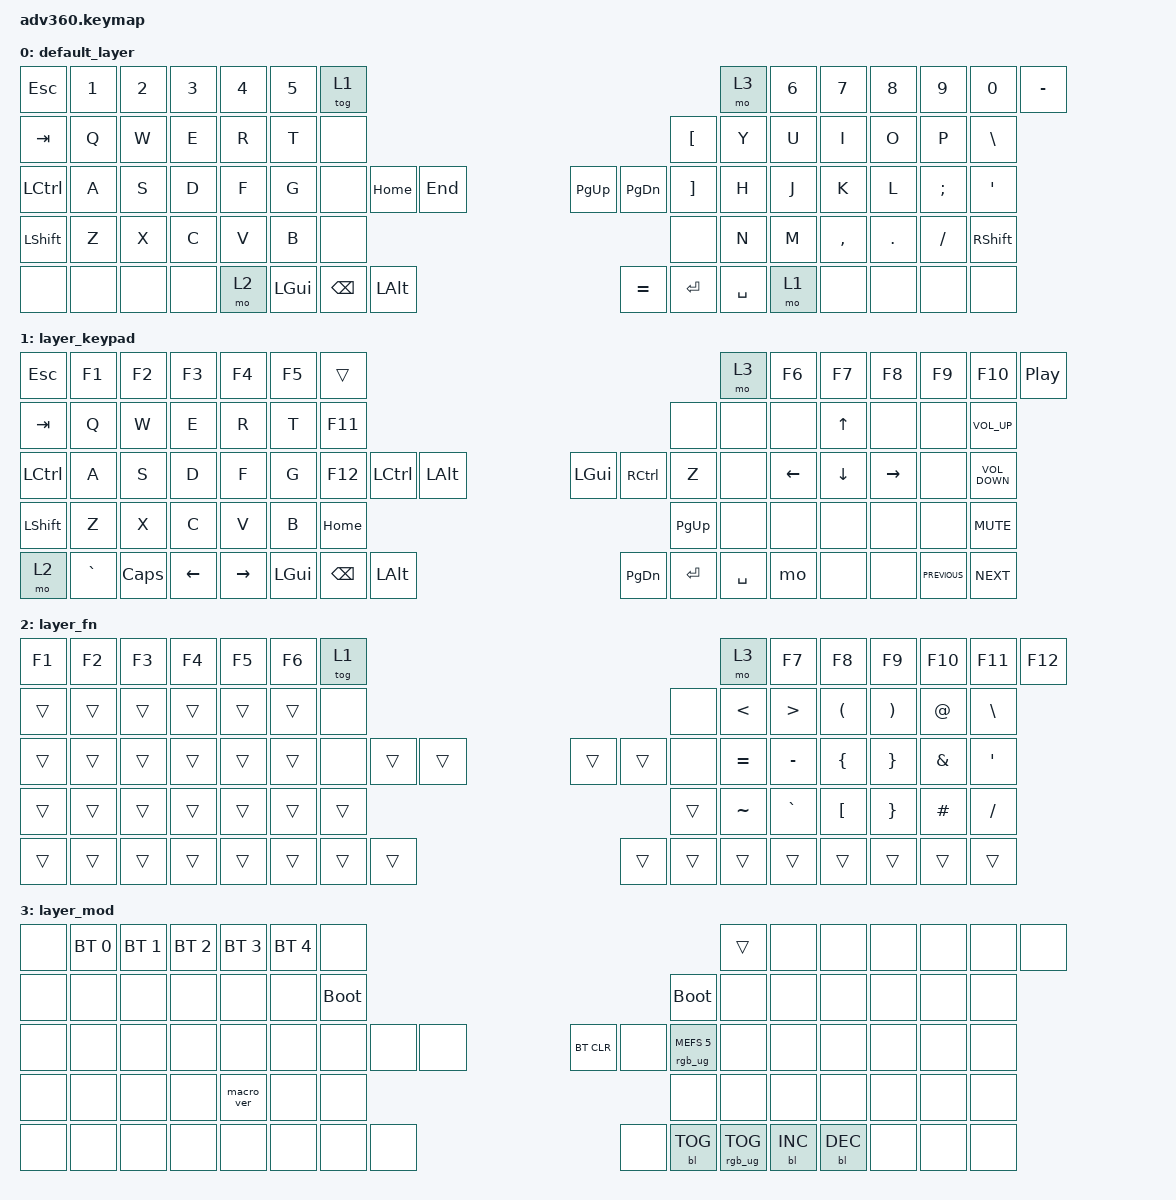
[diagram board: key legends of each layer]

/*
 * Copyright (c) 2020 The ZMK Contributors
 *
 * SPDX-License-Identifier: MIT
 */


/* THIS FILE WAS GENERATED!
 *
 * This file was generated automatically. You may or may not want to
 * edit it directly.
 */

#include <behaviors.dtsi>
#include <dt-bindings/zmk/keys.h>
#include <dt-bindings/zmk/bt.h>
#include <dt-bindings/zmk/rgb.h>
#include <dt-bindings/zmk/backlight.h>

/ {
  behaviors {
    #include "macros.dtsi"
    #include "version.dtsi"

    hm: homerow_mods {
        compatible = "zmk,behavior-hold-tap";
        label = "HOMEROW_MODS";
        #binding-cells = <2>;
        tapping-term-ms = <200>;
        quick_tap_ms = <175>;
        flavor = "tap-preferred";
        bindings = <&kp>, <&kp>;
    };
  };

    keymap {
        compatible = "zmk,keymap";


        default_layer {
            bindings = <
   &kp ESC  &kp N1  &kp N2  &kp N3  &kp N4  &kp N5                  &tog 1                                                                            &mo 3  &kp N6  &kp N7     &kp N8   &kp N9    &kp N0  &kp MINUS
   &kp TAB   &kp Q   &kp W   &kp E   &kp R   &kp T                   &none                                                                 &kp LEFT_BRACKET   &kp Y   &kp U      &kp I    &kp O     &kp P   &kp BSLH
 &kp LCTRL   &kp A   &kp S   &kp D   &kp F   &kp G                   &none  &kp HOME       &kp END                  &kp PG_UP  &kp PG_DN  &kp RIGHT_BRACKET   &kp H   &kp J      &kp K    &kp L  &kp SEMI    &kp SQT
 &kp LSHFT   &kp Z   &kp X   &kp C   &kp V   &kp B                                           &none                      &none                                 &kp N   &kp M  &kp COMMA  &kp DOT  &kp FSLH  &kp RSHFT
     &none   &none   &none   &none   &mo 2                    &kp LEFT_GUI  &kp BSPC  &kp LEFT_ALT                  &kp EQUAL  &kp ENTER          &kp SPACE           &mo 1      &none    &none     &none      &none
            >;
        };

        layer_keypad {
            bindings = <
   &kp ESC     &kp F1    &kp F2    &kp F3     &kp F4  &kp F5                  &trans                                                                         &mo 3  &kp F6    &kp F7        &kp F8     &kp F9         &kp F10   &kp C_PLAY_PAUSE
   &kp TAB      &kp Q     &kp W     &kp E      &kp R   &kp T                 &kp F11                                                                         &none   &none     &none  &kp UP_ARROW      &none           &none    &kp C_VOLUME_UP
 &kp LCTRL      &kp A     &kp S     &kp D      &kp F   &kp G                 &kp F12      &kp LCTRL      &kp LALT                   &kp LGUI  &kp RCTRL      &kp Z   &none  &kp LEFT      &kp DOWN  &kp RIGHT           &none  &kp C_VOLUME_DOWN
 &kp LSHFT      &kp Z     &kp X     &kp C      &kp V   &kp B                                             &kp HOME                  &kp PG_UP                         &none     &none         &none      &none           &none         &kp C_MUTE
     &mo 2  &kp GRAVE  &kp CAPS  &kp LEFT  &kp RIGHT                    &kp LEFT_GUI  &kp BACKSPACE  &kp LEFT_ALT                  &kp PG_DN  &kp ENTER  &kp SPACE               &mo         &none      &none  &kp C_PREVIOUS         &kp C_NEXT
            >;
        };

        layer_fn {
            bindings = <
 &kp F1  &kp F2  &kp F3  &kp F4  &kp F5  &kp F6            &tog 1                                                   &mo 3     &kp F7     &kp F8                &kp F9                &kp F10        &kp F11           &kp F12
 &trans  &trans  &trans  &trans  &trans  &trans             &none                                                   &none     &kp LT     &kp GT  &kp LEFT_PARENTHESIS  &kp RIGHT_PARENTHESIS    &kp AT_SIGN     &kp BACKSLASH
 &trans  &trans  &trans  &trans  &trans  &trans             &none  &trans  &trans                  &trans  &trans   &none  &kp EQUAL  &kp MINUS        &kp LEFT_BRACE        &kp RIGHT_BRACE  &kp AMPERSAND  &kp SINGLE_QUOTE
 &trans  &trans  &trans  &trans  &trans  &trans                            &trans                  &trans                  &kp TILDE  &kp GRAVE      &kp LEFT_BRACKET        &kp RIGHT_BRACE       &kp HASH         &kp SLASH
 &trans  &trans  &trans  &trans  &trans                    &trans  &trans  &trans                  &trans  &trans  &trans                &trans                &trans                 &trans         &trans            &trans
            >;
        };

        layer_mod {
            bindings = <
  &none  &bt BT_SEL 0  &bt BT_SEL 1  &bt BT_SEL 2  &bt BT_SEL 3  &bt BT_SEL 4                  &none                                                                          &trans   &none       &none       &none   &none   &none   &none
  &none         &none         &none         &none         &none         &none            &bootloader                                                                     &bootloader   &none       &none       &none   &none   &none   &none
  &none         &none         &none         &none         &none         &none                  &none   &none   &none                  &bt BT_CLR       &none  &rgb_ug RGB_MEFS_CMD 5   &none       &none       &none   &none   &none   &none
  &none         &none         &none         &none    &macro_ver         &none                                  &none                       &none                                       &none       &none       &none   &none   &none   &none
  &none         &none         &none         &none         &none                                &none   &none   &none                       &none  &bl BL_TOG         &rgb_ug RGB_TOG          &bl BL_INC  &bl BL_DEC   &none   &none   &none
            >;
        };

    };
};
